# ATmegaS64M1 device description
Architecture: AVR8; Family: megaAVR
Registers are 8-bit, access not given, no defined reset value unless marked. A register's access mark holds for its fields unless they carry their own. Offsets are from the block's base; [hi:lo] are bit positions; {n}, {i} and the like mark numbered series; 'fields as' and 'values as' point back to an identical list.

## LOCKBIT — Lockbits
Instances: LOCKBIT 0 in lockbits
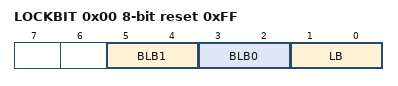
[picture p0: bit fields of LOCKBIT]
0x00 LOCKBIT reset 0xFF
  [5:4] BLB1 — Boot Loader Protection Mode
    0=LPM_SPM_DISABLE (LPM and SPM prohibited in Boot Section); 1=LPM_DISABLE (LPM prohibited in Boot Section); 2=SPM_DISABLE (SPM prohibited in Boot Section); 3=NO_LOCK (No lock on SPM and LPM in Boot Section)
  [3:2] BLB0 — Boot Loader Protection Mode
    0=LPM_SPM_DISABLE (LPM and SPM prohibited in Application Section); 1=LPM_DISABLE (LPM prohibited in Application Section); 2=SPM_DISABLE (SPM prohibited in Application Section); 3=NO_LOCK (No lock on SPM and LPM in Application Section)
  [1:0] LB — Memory Lock
    0=PROG_VER_DISABLED (Further programming and verification disabled); 2=PROG_DISABLED (Further programming disabled); 3=NO_LOCK (No memory lock features enabled)

## PORTB — I/O Port
Instances: PORTB 0x00
0x23 PINB — Port B Input Pins
0x24 DDRB — Port B Data Direction Register
0x25 PORTB — Port B Data Register

## PORTC — I/O Port
Instances: PORTC 0x00
0x26 PINC — Port C Input Pins
0x27 DDRC — Port C Data Direction Register
0x28 PORTC — Port C Data Register

## PORTD — I/O Port
Instances: PORTD 0x00
0x29 PIND — Port D Input Pins
0x2A DDRD — Port D Data Direction Register
0x2B PORTD — Port D Data Register

## PORTE — I/O Port
Instances: PORTE 0x00
0x2C PINE bits used 2:0 — Port E Input Pins
0x2D DDRE bits used 2:0 — Port E Data Direction Register
0x2E PORTE bits used 2:0 — Port E Data Register

## AC — Analog Comparator
Instances: AC 0x00
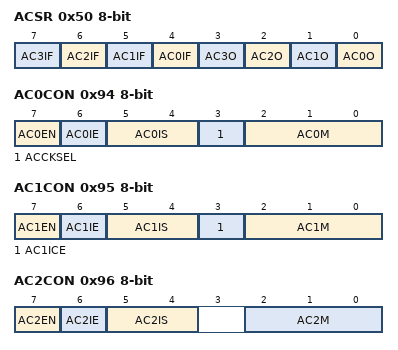
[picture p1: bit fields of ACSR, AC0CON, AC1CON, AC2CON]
0x50 ACSR — Analog Comparator Status Register
  [n+4] AC{n}IF (n=0..3) — Analog Comparator {n} Interrupt Flag Bit
  [n] AC{n}O (n=0..3) — Analog Comparator {n} Output Bit
0x94 AC0CON — Analog Comparator 0 Control Register
  [7] AC0EN — Analog Comparator 0 Enable Bit
  [6] AC0IE — Analog Comparator 0 Interrupt Enable Bit
  [5:4] AC0IS — Analog Comparator 0 Interrupt Select Bits
  [3] ACCKSEL — Analog Comparator Clock Select
  [2:0] AC0M — Analog Comparator 0 Multiplexer Register
0x95 AC1CON — Analog Comparator 1 Control Register
  [7] AC1EN — Analog Comparator 1 Enable Bit
  [6] AC1IE — Analog Comparator 1 Interrupt Enable Bit
  [5:4] AC1IS — Analog Comparator 1 Interrupt Select Bit
    0=INTERRUPT_ON_TOGGLE; 2=INTERRUPT_ON_FALLING_EDGE; 3=INTERRUPT_ON_RISING_EDGE
  [3] AC1ICE — Analog Comparator 1 Interrupt Capture Enable Bit
  [2:0] AC1M — Analog Comparator 1 Multiplexer Register
0x96 AC2CON — Analog Comparator 2 Control Register
  [7] AC2EN — Analog Comparator 2 Enable Bit
  [6] AC2IE — Analog Comparator 2 Interrupt Enable Bit
  [5:4] AC2IS — Analog Comparator 2 Interrupt Select Bit
    values as AC1CON.AC1IS
  [2:0] AC2M — Analog Comparator 2 Multiplexer Register
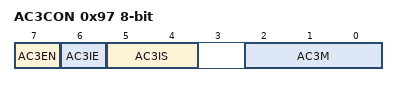
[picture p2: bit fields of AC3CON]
0x97 AC3CON — Analog Comparator 3 Control Register
  [7] AC3EN — Analog Comparator 3 Enable Bit
  [6] AC3IE — Analog Comparator 3 Interrupt Enable Bit
  [5:4] AC3IS — Analog Comparator 3 Interrupt Select Bit
    values as AC1CON.AC1IS
  [2:0] AC3M — Analog Comparator 3 Multiplexer Register

## DAC — Digital-to-Analog Converter
Instances: DAC 0x00
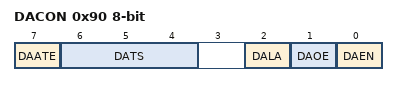
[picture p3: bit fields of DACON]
0x90 DACON — DAC Control Register
  [7] DAATE — DAC Auto Trigger Enable Bit
  [6:4] DATS — DAC Trigger Selection Bits
    0=ANALOG_COMPARATOR_0; 1=ANALOG_COMPARATOR_1; 2=EXTERNAL_INTERRUPT_REQUEST_0; 3=TIMER_COUNTER0_COMPARE_MATCH_A; 4=TIMER_COUNTER0_OVERFLOW; 5=TIMER_COUNTER1_COMPARE_MATCH_B; 6=TIMER_COUNTER1_OVERFLOW; 7=TIMER_COUNTER1_CAPTURE_EVENT
  [2] DALA — DAC Left Adjust
  [1] DAOE — DAC Output Enable
  [0] DAEN — DAC Enable Bit
0x91 DAC 16-bit — DAC Data Register
  [15:0] DAC — DAC Data Register Bits

## CPU — CPU Registers
Instances: CPU 0x00
0x39 GPIOR1 — General Purpose IO Register 1
  [7:0] GPIOR (bit 10 of the value upward) — General Purpose IO Register 1 bis
0x3A GPIOR2 — General Purpose IO Register 2
  [7:0] GPIOR (bit 20 of the value upward) — General Purpose IO Register 2 bis
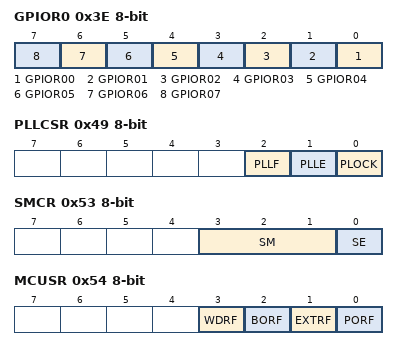
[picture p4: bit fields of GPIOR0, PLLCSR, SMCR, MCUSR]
0x3E GPIOR0 — General Purpose IO Register 0
  [n] GPIOR{n:02} (n=0..7) — General Purpose IO Register 0 bit {n}
0x49 PLLCSR — PLL Control And Status Register
  [2] PLLF — PLL Factor
  [1] PLLE — PLL Enable
  [0] PLOCK — PLL Lock Detector
0x53 SMCR — Sleep Mode Control Register
  [3:1] SM — Sleep Mode Select bits
    0=IDLE; 1=ADC (ADC Noise Reduction (If Available)); 2=PDOWN (Power Down); 6=STDBY (Standby)
  [0] SE — Sleep Enable
0x54 MCUSR — MCU Status Register
  [3] WDRF — Watchdog Reset Flag
  [2] BORF — Brown-out Reset Flag
  [1] EXTRF — External Reset Flag
  [0] PORF — Power-on reset flag
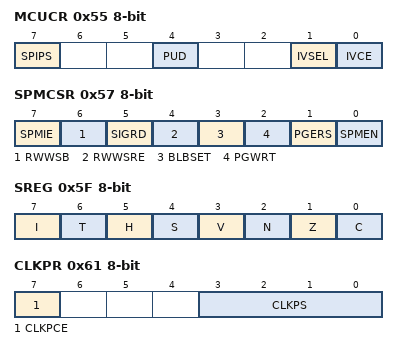
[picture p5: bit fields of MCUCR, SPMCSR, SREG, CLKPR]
0x55 MCUCR — MCU Control Register
  [7] SPIPS — SPI Pin Select
  [4] PUD — Pull-up disable
  [1] IVSEL — Interrupt Vector Select
  [0] IVCE — Interrupt Vector Change Enable
0x57 SPMCSR — Store Program Memory Control Register
  [7] SPMIE — SPM Interrupt Enable
  [6] RWWSB — Read While Write Section Busy
  [5] SIGRD — Signature Row Read
  [4] RWWSRE — Read While Write section read enable
  [3] BLBSET — Boot Lock Bit Set
  [2] PGWRT — Page Write
  [1] PGERS — Page Erase
  [0] SPMEN — Store Program Memory Enable
0x5D SP 16-bit — Stack Pointer
0x5F SREG — Status Register
  [7] I — Global Interrupt Enable
  [6] T — Bit Copy Storage
  [5] H — Half Carry Flag
  [4] S — Sign Bit
  [3] V — Two's Complement Overflow Flag
  [2] N — Negative Flag
  [1] Z — Zero Flag
  [0] C — Carry Flag
0x61 CLKPR
  [7] CLKPCE — Clock Prescaler Change Enable
  [3:0] CLKPS — Clock Prescaler Select
    0=1; 1=2; 2=4; 3=8; 4=16; 5=32; 6=64; 7=128; 8=256
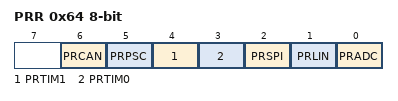
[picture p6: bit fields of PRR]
0x64 PRR — Power Reduction Register
  [6] PRCAN — Power Reduction CAN
  [5] PRPSC — Power Reduction PSC
  [4] PRTIM1 — Power Reduction Timer/Counter1
  [3] PRTIM0 — Power Reduction Timer/Counter0
  [2] PRSPI — Power Reduction Serial Peripheral Interface
  [1] PRLIN — Power Reduction LIN UART
  [0] PRADC — Power Reduction ADC
0x66 OSCCAL — Oscillator Calibration Value
  [7:0] OSCCAL — Oscillator Calibration
Value list OSCCAL_VALUE_ADDRESSES: 0=8_0_MHz
